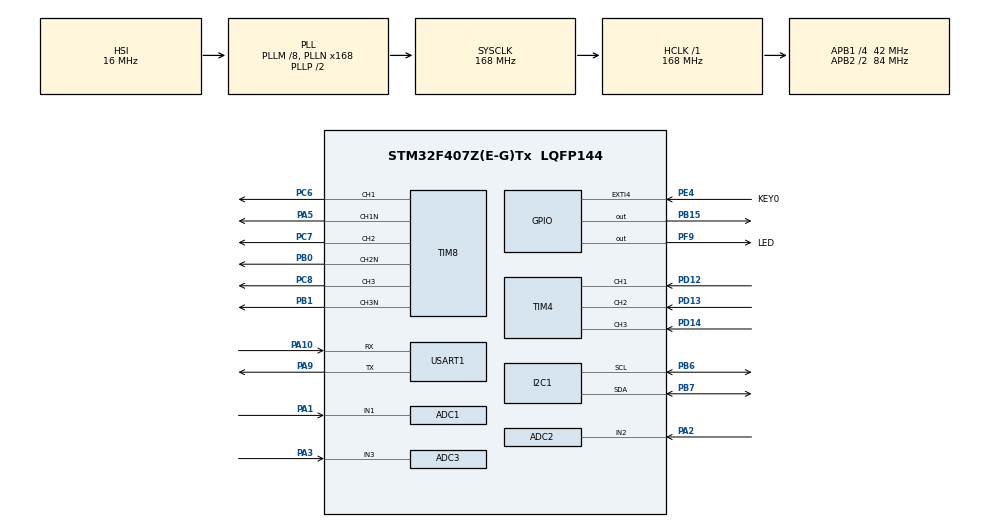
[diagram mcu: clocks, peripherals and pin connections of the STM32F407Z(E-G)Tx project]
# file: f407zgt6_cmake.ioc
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ADC1.Channel-2\#ChannelRegularConversion=ADC_CHANNEL_1
ADC1.NbrOfConversionFlag=1
ADC1.Rank-2\#ChannelRegularConversion=1
ADC1.SamplingTime-2\#ChannelRegularConversion=ADC_SAMPLETIME_3CYCLES
ADC1.master=1
ADC2.Channel-1\#ChannelRegularConversion=ADC_CHANNEL_2
ADC2.NbrOfConversionFlag=1
ADC2.Rank-1\#ChannelRegularConversion=1
ADC2.SamplingTime-1\#ChannelRegularConversion=ADC_SAMPLETIME_3CYCLES
ADC3.Channel-1\#ChannelRegularConversion=ADC_CHANNEL_3
ADC3.NbrOfConversionFlag=1
ADC3.Rank-1\#ChannelRegularConversion=1
ADC3.SamplingTime-1\#ChannelRegularConversion=ADC_SAMPLETIME_3CYCLES
Mcu.Family=STM32F4
Mcu.Name=STM32F407Z(E-G)Tx
Mcu.Package=LQFP144
NVIC.EXTI4_IRQn=true\:0\:0\:false\:false\:true\:true\:true\:true
NVIC.PriorityGroup=NVIC_PRIORITYGROUP_4
NVIC.TIM3_IRQn=true\:0\:0\:false\:false\:true\:true\:true\:true
NVIC.TIM4_IRQn=true\:0\:0\:false\:false\:true\:true\:true\:true
PA1.Signal=ADCx_IN1
PA10.Mode=Asynchronous
PA10.Signal=USART1_RX
PA13.Mode=Serial_Wire
PA13.Signal=SYS_JTMS-SWDIO
PA14.Mode=Serial_Wire
PA14.Signal=SYS_JTCK-SWCLK
PA2.Signal=ADCx_IN2
PA3.Signal=ADCx_IN3
PA5.Mode=PWM Generation1 CH1 CH1N
PA5.Signal=TIM8_CH1N
PA9.Mode=Asynchronous
PA9.Signal=USART1_TX
PB0.Mode=PWM Generation2 CH2 CH2N
PB0.Signal=TIM8_CH2N
PB1.Mode=PWM Generation3 CH3 CH3N
PB1.Signal=TIM8_CH3N
PB15.Signal=GPIO_Output
PB6.Mode=I2C
PB6.Signal=I2C1_SCL
PB7.Mode=I2C
PB7.Signal=I2C1_SDA
PC6.Signal=S_TIM8_CH1
PC7.Signal=S_TIM8_CH2
PC8.Signal=S_TIM8_CH3
PD12.Signal=S_TIM4_CH1
PD13.Signal=S_TIM4_CH2
PD14.Signal=S_TIM4_CH3
PE4.GPIO_Label=KEY0
PE4.Signal=GPXTI4
PF9.GPIO_Label=LED
PF9.Signal=GPIO_Output
PH0-OSC_IN.Mode=HSE-External-Oscillator
PH0-OSC_IN.Signal=RCC_OSC_IN
PH1-OSC_OUT.Mode=HSE-External-Oscillator
PH1-OSC_OUT.Signal=RCC_OSC_OUT
ProjectManager.HeapSize=0x200
ProjectManager.StackSize=0x400
ProjectManager.TargetToolchain=CMake
RCC.48MHZClocksFreq_Value=84000000
RCC.AHBFreq_Value=168000000
RCC.APB1CLKDivider=RCC_HCLK_DIV4
RCC.APB1Freq_Value=42000000
RCC.APB1TimFreq_Value=84000000
RCC.APB2CLKDivider=RCC_HCLK_DIV2
RCC.APB2Freq_Value=84000000
RCC.APB2TimFreq_Value=168000000
RCC.CortexFreq_Value=168000000
RCC.HCLKFreq_Value=168000000
RCC.HSE_VALUE=8000000
RCC.HSI_VALUE=16000000
RCC.LSE_VALUE=32768
RCC.PLLM=8
RCC.PLLN=168
RCC.SYSCLKFreq_VALUE=168000000
RCC.SYSCLKSource=RCC_SYSCLKSOURCE_PLLCLK
RCC.VCOOutputFreq_Value=336000000
SH.ADCx_IN1.0=ADC1_IN1,IN1
SH.ADCx_IN2.0=ADC2_IN2,IN2
SH.ADCx_IN3.0=ADC3_IN3,IN3
SH.S_TIM4_CH1.0=TIM4_CH1,Xored_Inputs_Hall_Sensor_Interface
SH.S_TIM4_CH2.0=TIM4_CH2,Xored_Inputs_Hall_Sensor_Interface
SH.S_TIM4_CH3.0=TIM4_CH3,Xored_Inputs_Hall_Sensor_Interface
SH.S_TIM8_CH1.0=TIM8_CH1,PWM Generation1 CH1 CH1N
SH.S_TIM8_CH2.0=TIM8_CH2,PWM Generation2 CH2 CH2N
SH.S_TIM8_CH3.0=TIM8_CH3,PWM Generation3 CH3 CH3N
TIM3.AutoReloadPreload=TIM_AUTORELOAD_PRELOAD_ENABLE
TIM4.AutoReloadPreload=TIM_AUTORELOAD_PRELOAD_ENABLE
TIM4.IC1Filter=5
TIM8.AutoReloadPreload=TIM_AUTORELOAD_PRELOAD_ENABLE
TIM8.Channel-PWM\ Generation1\ CH1\ CH1N=TIM_CHANNEL_1
TIM8.Channel-PWM\ Generation2\ CH2\ CH2N=TIM_CHANNEL_2
TIM8.Channel-PWM\ Generation3\ CH3\ CH3N=TIM_CHANNEL_3
TIM8.DeadTime=100
USART1.VirtualMode=VM_ASYNC
VP_TIM3_VS_ClockSourceINT.Mode=Internal
VP_TIM4_VS_ClockSourceINT.Mode=Internal
VP_TIM8_VS_ClockSourceINT.Mode=Internal
board=custom

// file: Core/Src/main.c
/* USER CODE BEGIN Header */
/**
 ******************************************************************************
 * @file           : main.c
 * @brief          : Main program body
 ******************************************************************************
 * @attention
 *
 * Copyright (c) 2025 STMicroelectronics.
 * All rights reserved.
 *
 * This software is licensed under terms that can be found in the LICENSE file
 * in the root directory of this software component.
 * If no LICENSE file comes with this software, it is provided AS-IS.
 *
 ******************************************************************************
 */
/* USER CODE END Header */
#include "main.h"
#include "adc.h"
#include "i2c.h"
#include "tim.h"
#include "usart.h"
#include "gpio.h"

/* USER CODE BEGIN Includes */
#include "mymain.h"

/* USER CODE END Includes */

void SystemClock_Config(void);

int main(void)
{

  /* MCU Configuration--------------------------------------------------------*/

  /* Reset of all peripherals, Initializes the Flash interface and the Systick. */
  HAL_Init();

  /* Configure the system clock */
  SystemClock_Config();

  /* Initialize all configured peripherals */
  MX_GPIO_Init();
  MX_TIM8_Init();
  MX_USART1_UART_Init();
  MX_ADC1_Init();
  MX_ADC2_Init();
  MX_ADC3_Init();
  MX_I2C1_Init();
  MX_TIM3_Init();
  MX_TIM4_Init();
  /* USER CODE BEGIN 2 */
    mymain();

  /* USER CODE END 2 */

  /* Infinite loop */
    while (1)
    {

    }
}

void SystemClock_Config(void)
{
  RCC_OscInitTypeDef RCC_OscInitStruct = {0};
  RCC_ClkInitTypeDef RCC_ClkInitStruct = {0};

  /** Configure the main internal regulator output voltage
  */
  __HAL_RCC_PWR_CLK_ENABLE();
  __HAL_PWR_VOLTAGESCALING_CONFIG(PWR_REGULATOR_VOLTAGE_SCALE1);

  /** Initializes the RCC Oscillators according to the specified parameters
  * in the RCC_OscInitTypeDef structure.
  */
  RCC_OscInitStruct.OscillatorType = RCC_OSCILLATORTYPE_HSI;
  RCC_OscInitStruct.HSIState = RCC_HSI_ON;
  RCC_OscInitStruct.HSICalibrationValue = RCC_HSICALIBRATION_DEFAULT;
  RCC_OscInitStruct.PLL.PLLState = RCC_PLL_ON;
  RCC_OscInitStruct.PLL.PLLSource = RCC_PLLSOURCE_HSI;
  RCC_OscInitStruct.PLL.PLLM = 8;
  RCC_OscInitStruct.PLL.PLLN = 168;
  RCC_OscInitStruct.PLL.PLLP = RCC_PLLP_DIV2;
  RCC_OscInitStruct.PLL.PLLQ = 4;
  if (HAL_RCC_OscConfig(&RCC_OscInitStruct) != HAL_OK)
  {
    Error_Handler();
  }

  /** Initializes the CPU, AHB and APB buses clocks
  */
  RCC_ClkInitStruct.ClockType = RCC_CLOCKTYPE_HCLK|RCC_CLOCKTYPE_SYSCLK
                              |RCC_CLOCKTYPE_PCLK1|RCC_CLOCKTYPE_PCLK2;
  RCC_ClkInitStruct.SYSCLKSource = RCC_SYSCLKSOURCE_PLLCLK;
  RCC_ClkInitStruct.AHBCLKDivider = RCC_SYSCLK_DIV1;
  RCC_ClkInitStruct.APB1CLKDivider = RCC_HCLK_DIV4;
  RCC_ClkInitStruct.APB2CLKDivider = RCC_HCLK_DIV2;

  if (HAL_RCC_ClockConfig(&RCC_ClkInitStruct, FLASH_LATENCY_5) != HAL_OK)
  {
    Error_Handler();
  }
}

void Error_Handler(void)
{
    __disable_irq();
    while (1)
    {
    }
}
#ifdef USE_FULL_ASSERT
/**
  * @brief  Reports the name of the source file and the source line number
  *         where the assert_param error has occurred.
  * @param  file: pointer to the source file name
  * @param  line: assert_param error line source number
  * @retval None
  */
void assert_failed(uint8_t *file, uint32_t line)
{
  /* USER CODE BEGIN 6 */
    /* User can add his own implementation to report the file name and line
       number, ex: printf("Wrong parameters value: file %s on line %d\r\n", file,
       line) */
  /* USER CODE END 6 */
}
#endif /* USE_FULL_ASSERT */
